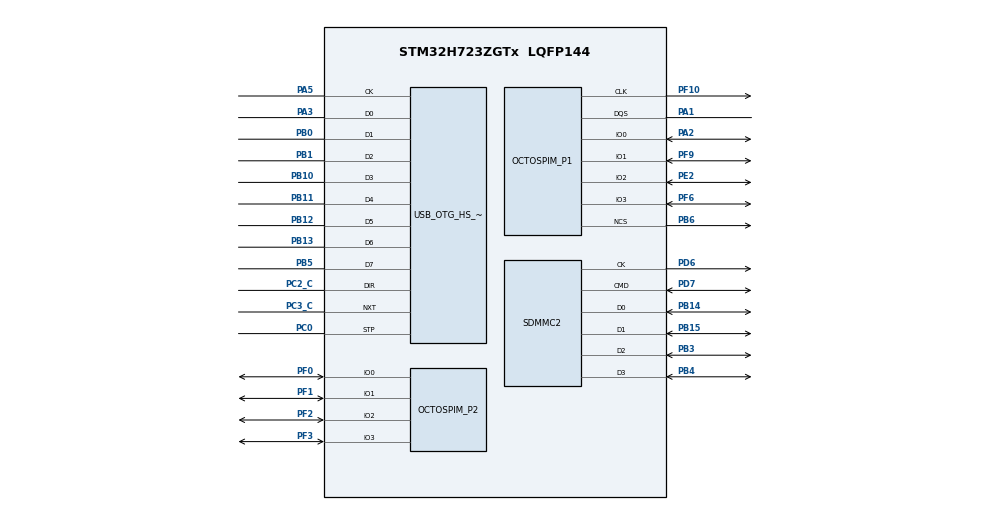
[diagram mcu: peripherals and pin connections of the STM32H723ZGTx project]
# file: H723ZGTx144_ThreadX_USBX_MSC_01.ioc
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CORTEX_M7.AccessPermission_S-Cortex_Memory_Protection_Unit_Region1_Settings_S=MPU_REGION_FULL_ACCESS
CORTEX_M7.AccessPermission_S-Cortex_Memory_Protection_Unit_Region2_Settings_S=MPU_REGION_FULL_ACCESS
CORTEX_M7.AccessPermission_S-Cortex_Memory_Protection_Unit_Region3_Settings_S=MPU_REGION_FULL_ACCESS
CORTEX_M7.AccessPermission_S-Cortex_Memory_Protection_Unit_Region4_Settings_S=MPU_REGION_FULL_ACCESS
CORTEX_M7.AccessPermission_Spec=MPU_REGION_FULL_ACCESS
CORTEX_M7.BaseAddress_S-Cortex_Memory_Protection_Unit_Region1_Settings_S=0x6000000
CORTEX_M7.BaseAddress_S-Cortex_Memory_Protection_Unit_Region2_Settings_S=0x30000000
CORTEX_M7.BaseAddress_S-Cortex_Memory_Protection_Unit_Region3_Settings_S=0x30004000
CORTEX_M7.BaseAddress_S-Cortex_Memory_Protection_Unit_Region4_Settings_S=0x90000000
CORTEX_M7.BaseAddress_Spec=0x24000000
CORTEX_M7.CPU_DCache=Enabled
CORTEX_M7.CPU_ICache=Enabled
CORTEX_M7.DisableExec_S-Cortex_Memory_Protection_Unit_Region3_Settings_S=MPU_INSTRUCTION_ACCESS_ENABLE
CORTEX_M7.DisableExec_Spec=MPU_INSTRUCTION_ACCESS_ENABLE
CORTEX_M7.Enable_S-Cortex_Memory_Protection_Unit_Region1_Settings_S=MPU_REGION_ENABLE
CORTEX_M7.Enable_S-Cortex_Memory_Protection_Unit_Region2_Settings_S=MPU_REGION_ENABLE
CORTEX_M7.Enable_S-Cortex_Memory_Protection_Unit_Region3_Settings_S=MPU_REGION_ENABLE
CORTEX_M7.Enable_S-Cortex_Memory_Protection_Unit_Region4_Settings_S=MPU_REGION_ENABLE
CORTEX_M7.Enable_S-Cortex_Memory_Protection_Unit_Region5_Settings_S=__NULL
CORTEX_M7.IsBufferable_S-Cortex_Memory_Protection_Unit_Region1_Settings_S=MPU_ACCESS_BUFFERABLE
CORTEX_M7.IsBufferable_S-Cortex_Memory_Protection_Unit_Region2_Settings_S=MPU_ACCESS_NOT_BUFFERABLE
CORTEX_M7.IsBufferable_S-Cortex_Memory_Protection_Unit_Region3_Settings_S=MPU_ACCESS_NOT_BUFFERABLE
CORTEX_M7.IsBufferable_S-Cortex_Memory_Protection_Unit_Region4_Settings_S=MPU_ACCESS_NOT_BUFFERABLE
CORTEX_M7.IsBufferable_Spec=MPU_ACCESS_NOT_BUFFERABLE
CORTEX_M7.IsCacheable_S-Cortex_Memory_Protection_Unit_Region2_Settings_S=MPU_ACCESS_NOT_CACHEABLE
CORTEX_M7.IsCacheable_S-Cortex_Memory_Protection_Unit_Region3_Settings_S=MPU_ACCESS_NOT_CACHEABLE
CORTEX_M7.IsCacheable_S-Cortex_Memory_Protection_Unit_Region4_Settings_S=MPU_ACCESS_CACHEABLE
CORTEX_M7.IsCacheable_Spec=MPU_ACCESS_NOT_CACHEABLE
CORTEX_M7.IsShareable_Spec=MPU_ACCESS_NOT_SHAREABLE
CORTEX_M7.Size_S-Cortex_Memory_Protection_Unit_Region1_Settings_S=MPU_REGION_SIZE_64KB
CORTEX_M7.Size_S-Cortex_Memory_Protection_Unit_Region2_Settings_S=MPU_REGION_SIZE_16KB
CORTEX_M7.Size_S-Cortex_Memory_Protection_Unit_Region3_Settings_S=MPU_REGION_SIZE_16KB
CORTEX_M7.Size_S-Cortex_Memory_Protection_Unit_Region4_Settings_S=MPU_REGION_SIZE_64MB
CORTEX_M7.Size_Spec=MPU_REGION_SIZE_512KB
CORTEX_M7.SubRegionDisable_S-Cortex_Memory_Protection_Unit_Region2_Settings_S=0x0
CORTEX_M7.SubRegionDisable_Spec=0
CORTEX_M7.TypeExtField_S-Cortex_Memory_Protection_Unit_Region2_Settings_S=MPU_TEX_LEVEL1
CORTEX_M7.TypeExtField_S-Cortex_Memory_Protection_Unit_Region3_Settings_S=MPU_TEX_LEVEL1
CORTEX_M7.TypeExtField_S-Cortex_Memory_Protection_Unit_Region4_Settings_S=MPU_TEX_LEVEL0
CORTEX_M7.TypeExtField_Spec=MPU_TEX_LEVEL1
CORTEX_M7.default_mode_Activation=1
Mcu.Family=STM32H7
Mcu.Name=STM32H723ZGTx
Mcu.Package=LQFP144
NVIC.OCTOSPI1_IRQn=true\:0\:0\:true\:false\:true\:false\:true\:true\:true
NVIC.OTG_HS_IRQn=true\:2\:0\:true\:false\:true\:false\:true\:true\:true
NVIC.PriorityGroup=NVIC_PRIORITYGROUP_4
NVIC.SDMMC2_IRQn=true\:5\:0\:true\:false\:true\:false\:true\:true\:true
NVIC.TIM4_IRQn=true\:15\:0\:true\:false\:true\:false\:false\:true\:true
NVIC.TimeBase=TIM4_IRQn
NVIC.TimeBaseIP=TIM4
OCTOSPI1.ChipSelectBoundary=11
OCTOSPI1.ChipSelectHighTime=2
OCTOSPI1.DelayBlockBypass=HAL_OSPI_DELAY_BLOCK_USED
OCTOSPI1.DelayHoldQuarterCycle=HAL_OSPI_DHQC_ENABLE
OCTOSPI1.DeviceSize=26
OCTOSPI1.FifoThreshold=4
OCTOSPI1.MemoryType=HAL_OSPI_MEMTYPE_APMEMORY
OCTOSPI1.Refresh=202
PA1.Mode=OCTOSPI1_Port1_DQS
PA1.Signal=OCTOSPIM_P1_DQS
PA13(JTMS/SWDIO).Mode=Serial_Wire
PA13(JTMS/SWDIO).Signal=DEBUG_JTMS-SWDIO
PA14(JTCK/SWCLK).Mode=Serial_Wire
PA14(JTCK/SWCLK).Signal=DEBUG_JTCK-SWCLK
PA2.Mode=OCTOSPI1_IOL_Port1L
PA2.Signal=OCTOSPIM_P1_IO0
PA3.Mode=Device_HS
PA3.Signal=USB_OTG_HS_ULPI_D0
PA5.Mode=Device_HS
PA5.Signal=USB_OTG_HS_ULPI_CK
PB0.Mode=Device_HS
PB0.Signal=USB_OTG_HS_ULPI_D1
PB1.Mode=Device_HS
PB1.Signal=USB_OTG_HS_ULPI_D2
PB10.Mode=Device_HS
PB10.Signal=USB_OTG_HS_ULPI_D3
PB11.Mode=Device_HS
PB11.Signal=USB_OTG_HS_ULPI_D4
PB12.Mode=Device_HS
PB12.Signal=USB_OTG_HS_ULPI_D5
PB13.Mode=Device_HS
PB13.Signal=USB_OTG_HS_ULPI_D6
PB14.Mode=SD_4_bits_Wide_bus
PB14.Signal=SDMMC2_D0
PB15.Mode=SD_4_bits_Wide_bus
PB15.Signal=SDMMC2_D1
PB3(JTDO/TRACESWO).Mode=SD_4_bits_Wide_bus
PB3(JTDO/TRACESWO).Signal=SDMMC2_D2
PB4(NJTRST).Mode=SD_4_bits_Wide_bus
PB4(NJTRST).Signal=SDMMC2_D3
PB5.Mode=Device_HS
PB5.Signal=USB_OTG_HS_ULPI_D7
PB6.Mode=OCTOSPI1_Port1_NCS
PB6.Signal=OCTOSPIM_P1_NCS
PC0.Mode=Device_HS
PC0.Signal=USB_OTG_HS_ULPI_STP
PC2_C.Mode=Device_HS
PC2_C.Signal=USB_OTG_HS_ULPI_DIR
PC3_C.Mode=Device_HS
PC3_C.Signal=USB_OTG_HS_ULPI_NXT
PD6.Mode=SD_4_bits_Wide_bus
PD6.Signal=SDMMC2_CK
PD7.Mode=SD_4_bits_Wide_bus
PD7.Signal=SDMMC2_CMD
PE2.Mode=OCTOSPI1_IOL_Port1L
PE2.Signal=OCTOSPIM_P1_IO2
PF0.Mode=OCTOSPI1_IOH_Port2L
PF0.Signal=OCTOSPIM_P2_IO0
PF1.Mode=OCTOSPI1_IOH_Port2L
PF1.Signal=OCTOSPIM_P2_IO1
PF10.Mode=O1_P1_CLK
PF10.Signal=OCTOSPIM_P1_CLK
PF2.Mode=OCTOSPI1_IOH_Port2L
PF2.Signal=OCTOSPIM_P2_IO2
PF3.Mode=OCTOSPI1_IOH_Port2L
PF3.Signal=OCTOSPIM_P2_IO3
PF6.Mode=OCTOSPI1_IOL_Port1L
PF6.Signal=OCTOSPIM_P1_IO3
PF9.Mode=OCTOSPI1_IOL_Port1L
PF9.Signal=OCTOSPIM_P1_IO1
PH0-OSC_IN.Mode=HSE-External-Clock-Source
PH0-OSC_IN.Signal=RCC_OSC_IN
ProjectManager.HeapSize=0x1000
ProjectManager.StackSize=0x4000
ProjectManager.TargetToolchain=STM32CubeIDE
RCC.ADCFreq_Value=170000000
RCC.APB1Freq_Value=137500000
RCC.APB2Freq_Value=137500000
RCC.APB3Freq_Value=137500000
RCC.APB4Freq_Value=137500000
RCC.CortexFreq_Value=550000000
RCC.D1PPRE=RCC_APB3_DIV2
RCC.D2PPRE1=RCC_APB1_DIV2
RCC.D2PPRE2=RCC_APB2_DIV2
RCC.D3PPRE=RCC_APB4_DIV2
RCC.DIVM1=5
RCC.DIVM2=5
RCC.DIVM3=25
RCC.DIVN1=55
RCC.DIVN2=34
RCC.DIVN3=96
RCC.DIVP1=1
RCC.DIVQ1=11
RCC.DIVQ3=4
RCC.DIVR2=4
RCC.HCLKFreq_Value=275000000
RCC.HPRE=RCC_HCLK_DIV2
RCC.HSE_VALUE=50000000
RCC.PLLSourceVirtual=RCC_PLLSOURCE_HSE
RCC.QSPICLockSelection=RCC_OSPICLKSOURCE_PLL2
RCC.RCC_TIM_PRescaler_Selection=RCC_TIMPRES_DESACTIVATED
RCC.SYSCLKFreq_VALUE=550000000
RCC.SYSCLKSource=RCC_SYSCLKSOURCE_PLLCLK
RCC.USBCLockSelection=RCC_USBCLKSOURCE_PLL3
RCC.USBFreq_Value=48000000
SDMMC2.ClockDiv=0
SDMMC2.HardwareFlowControl=SDMMC_HARDWARE_FLOW_CONTROL_ENABLE
STMicroelectronics.X-CUBE-AZRTOS-H7.3.4.0.ENABLE_CACHE_MAINTENANCE=true
STMicroelectronics.X-CUBE-AZRTOS-H7.3.4.0.FILEX_APPLICATION_THREAD_STACK_SIZE=4096
STMicroelectronics.X-CUBE-AZRTOS-H7.3.4.0.FX_APP_MEM_POOL_SIZE=1024*16
STMicroelectronics.X-CUBE-AZRTOS-H7.3.4.0.FX_DISABLE_ERROR_CHECKING=1
STMicroelectronics.X-CUBE-AZRTOS-H7.3.4.0.FX_DRIVER_SD_INIT=0
STMicroelectronics.X-CUBE-AZRTOS-H7.3.4.0.FX_ENABLE_EXFAT=1
STMicroelectronics.X-CUBE-AZRTOS-H7.3.4.0.FX_FAT_MAP_SIZE=1024
STMicroelectronics.X-CUBE-AZRTOS-H7.3.4.0.FileXCcFileOoSystemJjFileXJjCore=true
STMicroelectronics.X-CUBE-AZRTOS-H7.3.4.0.InterfacesCcFileOoSystemJjFileXOoSDOointerface=true
STMicroelectronics.X-CUBE-AZRTOS-H7.3.4.0.MAX_FAT_CACHE_NB_BIT=10
STMicroelectronics.X-CUBE-AZRTOS-H7.3.4.0.MAX_POWER_IN_MILLI_AMPER=500
STMicroelectronics.X-CUBE-AZRTOS-H7.3.4.0.MAX_SECTOR_CACHE_NB_BIT=10
STMicroelectronics.X-CUBE-AZRTOS-H7.3.4.0.SD_INSTANCE=1
STMicroelectronics.X-CUBE-AZRTOS-H7.3.4.0.TX_APP_CREATION=1
STMicroelectronics.X-CUBE-AZRTOS-H7.3.4.0.TX_APP_GENERATE_INIT_CODE=true
STMicroelectronics.X-CUBE-AZRTOS-H7.3.4.0.TX_APP_MEM_POOL_SIZE=1024*15
STMicroelectronics.X-CUBE-AZRTOS-H7.3.4.0.TX_APP_STACK_SIZE=4096
STMicroelectronics.X-CUBE-AZRTOS-H7.3.4.0.TX_TIMER_THREAD_STACK_SIZE=2048
STMicroelectronics.X-CUBE-AZRTOS-H7.3.4.0.TX_TIMER_TICKS_PER_SECOND=1000
STMicroelectronics.X-CUBE-AZRTOS-H7.3.4.0.ThreadXCcRTOSJjThreadXJjCore=true
STMicroelectronics.X-CUBE-AZRTOS-H7.3.4.0.USBXCcUSBJjUSBXJjCoreSystem=true
STMicroelectronics.X-CUBE-AZRTOS-H7.3.4.0.USBXCcUSBJjUSBXJjUXOoDeviceOoClassOoSTORAGE=true
STMicroelectronics.X-CUBE-AZRTOS-H7.3.4.0.USBXCcUSBJjUSBXJjUXOoDeviceOoControllers=true
STMicroelectronics.X-CUBE-AZRTOS-H7.3.4.0.USBXCcUSBJjUSBXJjUXOoDeviceOoCoreStack=true
STMicroelectronics.X-CUBE-AZRTOS-H7.3.4.0.USBX_DEVICE_APP_THREAD_Size=4096
STMicroelectronics.X-CUBE-AZRTOS-H7.3.4.0.USBX_DEVICE_SYS_SIZE=1024*15
STMicroelectronics.X-CUBE-AZRTOS-H7.3.4.0.UX_ALIGN_MIN=UX_ALIGN_32
STMicroelectronics.X-CUBE-AZRTOS-H7.3.4.0.UX_DEBUG_LOG_SIZE=4096
STMicroelectronics.X-CUBE-AZRTOS-H7.3.4.0.UX_DEVICE_APP_MEM_POOL_SIZE=1024*32
STMicroelectronics.X-CUBE-AZRTOS-H7.3.4.0.UX_PERIODIC_RATE=1000
STMicroelectronics.X-CUBE-AZRTOS-H7.3.4.0.UX_SLAVE_REQUEST_DATA_MAX_LENGTH=4096
STMicroelectronics.X-CUBE-AZRTOS-H7.3.4.0.UX_THREAD_STACK_SIZE=4096
STMicroelectronics.X-CUBE-AZRTOS-H7.3.4.0_IsAnAzureRtosMw=true
TIM7.AutoReloadPreload=TIM_AUTORELOAD_PRELOAD_ENABLE
TIM7.Period=50000-1
TIM7.Prescaler=135-1
USB_OTG_HS.VirtualMode-Device_HS=Device_HS
USB_OTG_HS.dma_enable-Device_HS=ENABLE
VP_MEMORYMAP_VS_MEMORYMAP.Mode=CurAppReg
VP_OCTOSPI1_VS_octo.Mode=octo_mode
VP_STMicroelectronics.X-CUBE-AZRTOS-H7_VS_FileOoSystemJjFileX_6.4.0_3.4.0.Mode=FileOoSystemJjFileX
VP_STMicroelectronics.X-CUBE-AZRTOS-H7_VS_FileOoSystemJjInterfaces_3.4.0_3.4.0.Mode=FileOoSystemJjInterfaces
VP_STMicroelectronics.X-CUBE-AZRTOS-H7_VS_RTOSJjThreadX_6.4.0_3.4.0.Mode=RTOSJjThreadX
VP_STMicroelectronics.X-CUBE-AZRTOS-H7_VS_USBJjUSBX_6.4.0_3.4.0.Mode=USBJjUSBX
VP_SYS_VS_tim4.Mode=TIM4
VP_TIM3_VS_ClockSourceINT.Mode=Internal
VP_TIM7_VS_ClockSourceINT.Mode=Enable_Timer
board=custom

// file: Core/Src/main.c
/* USER CODE BEGIN Header */
/**
  ******************************************************************************
  * @file           : main.c
  * @brief          : Main program body
  ******************************************************************************
  * @attention
  *
  * Copyright (c) 2025 STMicroelectronics.
  * All rights reserved.
  *
  * This software is licensed under terms that can be found in the LICENSE file
  * in the root directory of this software component.
  * If no LICENSE file comes with this software, it is provided AS-IS.
  *
  ******************************************************************************
  */
/* USER CODE END Header */
#include "app_threadx.h"
#include "main.h"
#include "octospi.h"
#include "sdmmc.h"
#include "tim.h"
#include "gpio.h"

/* USER CODE BEGIN PV */
HAL_SD_CardInfoTypeDef                     USBD_SD_CardInfo;
/* USER CODE END PV */

void SystemClock_Config(void);
static void MPU_Config(void);

int main(void)
{

  /* USER CODE BEGIN 1 */
  UINT status;
  /* USER CODE END 1 */

  /* MPU Configuration--------------------------------------------------------*/
  MPU_Config();

  /* Enable the CPU Cache */

  /* Enable I-Cache---------------------------------------------------------*/
  SCB_EnableICache();

  /* Enable D-Cache---------------------------------------------------------*/
  SCB_EnableDCache();

  /* MCU Configuration--------------------------------------------------------*/

  /* Reset of all peripherals, Initializes the Flash interface and the Systick. */
  HAL_Init();

  /* Configure the system clock */
  SystemClock_Config();

  /* Initialize all configured peripherals */
  MX_GPIO_Init();
  MX_TIM3_Init();
  MX_TIM7_Init();
  MX_OCTOSPI1_Init();
  MX_SDMMC2_SD_Init();
  /* USER CODE BEGIN 2 */

  /* Check if SD card is present */
  //if(HAL_GPIO_ReadPin(GPIOG, GPIO_PIN_12) == GPIO_PIN_SET) { Error_Handler(); }
  /* Get SD card info 存到 hsd2 里
   * 供后续 USBD_STORAGE_GetMediaLastLba() 和 USBD_STORAGE_GetMediaBlocklength() 获取信息
   */
  status = HAL_SD_GetCardInfo(&hsd2, &USBD_SD_CardInfo);

  if (status != HAL_OK)
  {
    Error_Handler();
  }

  /* USER CODE END 2 */

  MX_ThreadX_Init();

  /* We should never get here as control is now taken by the scheduler */

  /* Infinite loop */
  while (1)
  {

  }
}

void SystemClock_Config(void)
{
  RCC_OscInitTypeDef RCC_OscInitStruct = {0};
  RCC_ClkInitTypeDef RCC_ClkInitStruct = {0};

  /** Supply configuration update enable
  */
  HAL_PWREx_ConfigSupply(PWR_LDO_SUPPLY);

  /** Configure the main internal regulator output voltage
  */
  __HAL_PWR_VOLTAGESCALING_CONFIG(PWR_REGULATOR_VOLTAGE_SCALE0);

  while(!__HAL_PWR_GET_FLAG(PWR_FLAG_VOSRDY)) {}

  /** Initializes the RCC Oscillators according to the specified parameters
  * in the RCC_OscInitTypeDef structure.
  */
  RCC_OscInitStruct.OscillatorType = RCC_OSCILLATORTYPE_HSE;
  RCC_OscInitStruct.HSEState = RCC_HSE_BYPASS;
  RCC_OscInitStruct.PLL.PLLState = RCC_PLL_ON;
  RCC_OscInitStruct.PLL.PLLSource = RCC_PLLSOURCE_HSE;
  RCC_OscInitStruct.PLL.PLLM = 5;
  RCC_OscInitStruct.PLL.PLLN = 55;
  RCC_OscInitStruct.PLL.PLLP = 1;
  RCC_OscInitStruct.PLL.PLLQ = 11;
  RCC_OscInitStruct.PLL.PLLR = 2;
  RCC_OscInitStruct.PLL.PLLRGE = RCC_PLL1VCIRANGE_3;
  RCC_OscInitStruct.PLL.PLLVCOSEL = RCC_PLL1VCOWIDE;
  RCC_OscInitStruct.PLL.PLLFRACN = 0;
  if (HAL_RCC_OscConfig(&RCC_OscInitStruct) != HAL_OK)
  {
    Error_Handler();
  }

  /** Initializes the CPU, AHB and APB buses clocks
  */
  RCC_ClkInitStruct.ClockType = RCC_CLOCKTYPE_HCLK|RCC_CLOCKTYPE_SYSCLK
                              |RCC_CLOCKTYPE_PCLK1|RCC_CLOCKTYPE_PCLK2
                              |RCC_CLOCKTYPE_D3PCLK1|RCC_CLOCKTYPE_D1PCLK1;
  RCC_ClkInitStruct.SYSCLKSource = RCC_SYSCLKSOURCE_PLLCLK;
  RCC_ClkInitStruct.SYSCLKDivider = RCC_SYSCLK_DIV1;
  RCC_ClkInitStruct.AHBCLKDivider = RCC_HCLK_DIV2;
  RCC_ClkInitStruct.APB3CLKDivider = RCC_APB3_DIV2;
  RCC_ClkInitStruct.APB1CLKDivider = RCC_APB1_DIV2;
  RCC_ClkInitStruct.APB2CLKDivider = RCC_APB2_DIV2;
  RCC_ClkInitStruct.APB4CLKDivider = RCC_APB4_DIV2;

  if (HAL_RCC_ClockConfig(&RCC_ClkInitStruct, FLASH_LATENCY_3) != HAL_OK)
  {
    Error_Handler();
  }
}

/* USER CODE BEGIN 4 */
void _Error_Handler(const char * file, uint32_t line)
{
  /* USER CODE BEGIN Error_Handler_Debug */
  /* User can add his own implementation to report the HAL error return state */
  __disable_irq();
  while (1)
  {
  }
  /* USER CODE END Error_Handler_Debug */
}
/* USER CODE END 4 */

 /* MPU Configuration */

void MPU_Config(void)
{
  MPU_Region_InitTypeDef MPU_InitStruct = {0};

  /* Disables the MPU */
  HAL_MPU_Disable();

  /** Initializes and configures the Region and the memory to be protected
  */
  MPU_InitStruct.Enable = MPU_REGION_ENABLE;
  MPU_InitStruct.Number = MPU_REGION_NUMBER0;
  MPU_InitStruct.BaseAddress = 0x24000000;
  MPU_InitStruct.Size = MPU_REGION_SIZE_512KB;
  MPU_InitStruct.SubRegionDisable = 0;
  MPU_InitStruct.TypeExtField = MPU_TEX_LEVEL1;
  MPU_InitStruct.AccessPermission = MPU_REGION_FULL_ACCESS;
  MPU_InitStruct.DisableExec = MPU_INSTRUCTION_ACCESS_ENABLE;
  MPU_InitStruct.IsShareable = MPU_ACCESS_NOT_SHAREABLE;
  MPU_InitStruct.IsCacheable = MPU_ACCESS_NOT_CACHEABLE;
  MPU_InitStruct.IsBufferable = MPU_ACCESS_NOT_BUFFERABLE;

  HAL_MPU_ConfigRegion(&MPU_InitStruct);

  /** Initializes and configures the Region and the memory to be protected
  */
  MPU_InitStruct.Number = MPU_REGION_NUMBER1;
  MPU_InitStruct.BaseAddress = 0x6000000;
  MPU_InitStruct.Size = MPU_REGION_SIZE_64KB;
  MPU_InitStruct.SubRegionDisable = 0x0;
  MPU_InitStruct.TypeExtField = MPU_TEX_LEVEL0;
  MPU_InitStruct.IsBufferable = MPU_ACCESS_BUFFERABLE;

  HAL_MPU_ConfigRegion(&MPU_InitStruct);

  /** Initializes and configures the Region and the memory to be protected
  */
  MPU_InitStruct.Number = MPU_REGION_NUMBER2;
  MPU_InitStruct.BaseAddress = 0x30000000;
  MPU_InitStruct.Size = MPU_REGION_SIZE_16KB;
  MPU_InitStruct.TypeExtField = MPU_TEX_LEVEL1;
  MPU_InitStruct.IsBufferable = MPU_ACCESS_NOT_BUFFERABLE;

  HAL_MPU_ConfigRegion(&MPU_InitStruct);

  /** Initializes and configures the Region and the memory to be protected
  */
  MPU_InitStruct.Number = MPU_REGION_NUMBER3;
  MPU_InitStruct.BaseAddress = 0x30004000;

  HAL_MPU_ConfigRegion(&MPU_InitStruct);

  /** Initializes and configures the Region and the memory to be protected
  */
  MPU_InitStruct.Number = MPU_REGION_NUMBER4;
  MPU_InitStruct.BaseAddress = 0x90000000;
  MPU_InitStruct.Size = MPU_REGION_SIZE_64MB;
  MPU_InitStruct.TypeExtField = MPU_TEX_LEVEL0;
  MPU_InitStruct.IsCacheable = MPU_ACCESS_CACHEABLE;

  HAL_MPU_ConfigRegion(&MPU_InitStruct);
  /* Enables the MPU */
  HAL_MPU_Enable(MPU_PRIVILEGED_DEFAULT);

}

void HAL_TIM_PeriodElapsedCallback(TIM_HandleTypeDef *htim)
{
  if (htim->Instance == TIM4)
  {
    HAL_IncTick();
  }
}

void Error_Handler(void)
{
  __disable_irq();
  while (1)
  {
  }
}
